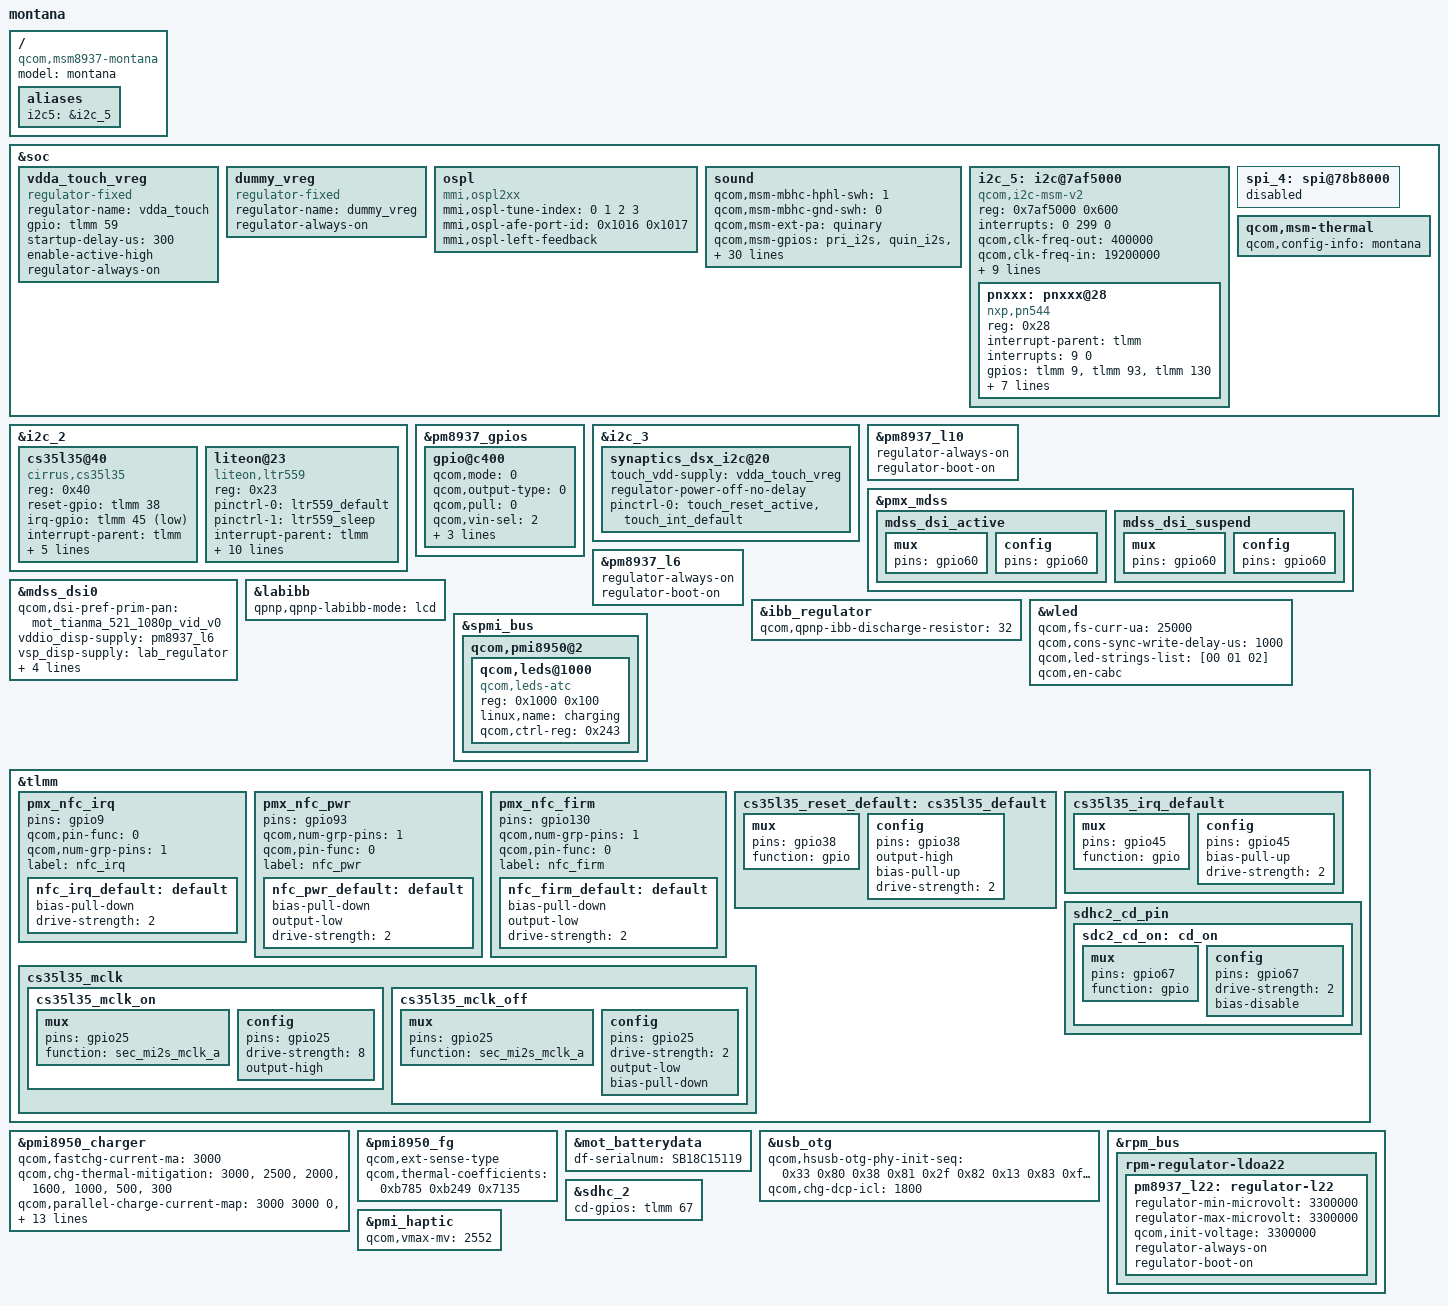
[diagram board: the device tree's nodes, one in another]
/* Copyright (c) 2016, Motorola Mobility Inc. All rights reserved.
 *
 * This program is free software; you can redistribute it and/or modify
 * it under the terms of the GNU General Public License version 2 and
 * only version 2 as published by the Free Software Foundation.
 *
 * This program is distributed in the hope that it will be useful,
 * but WITHOUT ANY WARRANTY; without even the implied warranty of
 * MERCHANTABILITY or FITNESS FOR A PARTICULAR PURPOSE.  See the
 * GNU General Public License for more details.
 */

#include "msm8937-moto-common.dtsi"
#include "dsi-panel-mot-tianma-521-1080p-video.dtsi"
#include "dsi-panel-mot-inx-521-1080p-video.dtsi"
#include "msm8937-camera-sensor-mot-montana.dtsi"
#include "msm8937-montana-fps.dtsi"

 / {
	model = "montana";
	compatible = "qcom,msm8937-montana", "qcom,msm8937-moto",
			"qcom,msm8937";
	aliases {
		i2c5 = &i2c_5;
	};
};

&soc {
	vdda_touch_vreg: vdda_touch_vreg {
		compatible = "regulator-fixed";
		regulator-name = "vdda_touch";
		gpio = <&tlmm 59 0>;
		startup-delay-us = <300>;
		enable-active-high;
		regulator-always-on;
	};

	dummy_vreg: dummy_vreg {
		compatible = "regulator-fixed";
		status = "ok";
		regulator-name = "dummy_vreg";
		regulator-always-on;
	};

	ospl {
		compatible = "mmi,ospl2xx";
		status = "ok";
		mmi,ospl-tune-index = <0 1 2 3>;
		mmi,ospl-afe-port-id = <0x1016 0x1017>;
		mmi,ospl-left-feedback;
	};

	sound {
		qcom,msm-mbhc-hphl-swh = <1>;
		qcom,msm-mbhc-gnd-swh = <0>;
		qcom,msm-ext-pa = "quinary";
		/delete-property/ qcom,cdc-us-euro-gpios;
		/delete-property/ qcom,msm-micbias1-ext-cap;
		/delete-property/ qcom,msm-micbias2-ext-cap;
		qcom,msm-gpios =
			"pri_i2s",
			"quin_i2s",
			"cs35l35_mclk";
		qcom,pinctrl-names =
			"all_off",
			"pri_i2s_act",
			"quin_act",
			"quin_pri_i2s_act",
			"cs35l35_mclk_act",
			"cs35l35_mclk_pri_i2s_act",
			"cs35l35_mclk_quin_act",
			"cs35l35_mclk_quin_pri_i2s_act";
		pinctrl-names =
			"all_off",
			"pri_i2s_act",
			"quin_act",
			"quin_pri_i2s_act",
			"cs35l35_mclk_act",
			"cs35l35_mclk_pri_i2s_act",
			"cs35l35_mclk_quin_act",
			"cs35l35_mclk_quin_pri_i2s_act";
		pinctrl-0 = <&cdc_pdm_lines_sus &cdc_pdm_lines_2_sus
			&pri_tlmm_lines_sus &pri_tlmm_ws_sus &cs35l35_mclk_off>;
		pinctrl-1 = <&cdc_pdm_lines_act &cdc_pdm_lines_2_act
			&pri_tlmm_lines_sus &pri_tlmm_ws_sus &cs35l35_mclk_off>;
		pinctrl-2 = <&cdc_pdm_lines_sus &cdc_pdm_lines_2_sus
			&pri_tlmm_lines_act &pri_tlmm_ws_act &cs35l35_mclk_off>;
		pinctrl-3 = <&cdc_pdm_lines_act &cdc_pdm_lines_2_act
			&pri_tlmm_lines_act &pri_tlmm_ws_act &cs35l35_mclk_off>;
		pinctrl-4 = <&cdc_pdm_lines_sus &cdc_pdm_lines_2_sus
			&pri_tlmm_lines_sus &pri_tlmm_ws_sus &cs35l35_mclk_on>;
		pinctrl-5 = <&cdc_pdm_lines_act &cdc_pdm_lines_2_act
			&pri_tlmm_lines_sus &pri_tlmm_ws_sus &cs35l35_mclk_on>;
		pinctrl-6 = <&cdc_pdm_lines_sus &cdc_pdm_lines_2_sus
			&pri_tlmm_lines_act &pri_tlmm_ws_act &cs35l35_mclk_on>;
		pinctrl-7 = <&cdc_pdm_lines_act &cdc_pdm_lines_2_act
			&pri_tlmm_lines_act &pri_tlmm_ws_act &cs35l35_mclk_on>;
	};

	i2c_5: i2c@7af5000 { /* BLSP2 QUP1 */
		status = "okay";
		compatible = "qcom,i2c-msm-v2";
		#address-cells = <1>;
		#size-cells = <0>;
		reg-names = "qup_phys_addr";
		reg = <0x7af5000 0x600>;
		interrupt-names = "qup_irq";
		interrupts = <0 299 0>;
		qcom,clk-freq-out = <400000>;
		qcom,clk-freq-in  = <19200000>;
		clock-names = "iface_clk", "core_clk";
		clocks = <&clock_gcc clk_gcc_blsp2_ahb_clk>,
			<&clock_gcc clk_gcc_blsp2_qup1_i2c_apps_clk>;

		pinctrl-names = "i2c_active", "i2c_sleep";
		pinctrl-0 = <&i2c_5_active>;
		pinctrl-1 = <&i2c_5_sleep>;
		qcom,noise-rjct-scl = <0>;
		qcom,noise-rjct-sda = <0>;
		qcom,master-id = <84>;
		dmas = <&dma_blsp2 4 64 0x20000020 0x20>,
			<&dma_blsp2 5 32 0x20000020 0x20>;
		dma-names = "tx", "rx";
	};

        spi_4: spi@78b8000 { /* BLSP1 QUP4 */
                status = "disabled";
                /delete-node/ stml0xx@0;
        };

	qcom,msm-thermal {
		qcom,config-info = "montana";
	};
};

&i2c_2 {
	/delete-node/ adv7533@39;
	/delete-node/ pericom-type-c@1d;

	cs35l35@40 {
		compatible = "cirrus,cs35l35";
		reg = <0x40>;
		reset-gpio = <&tlmm 38 0>;
		irq-gpio = <&tlmm 45 1>;
		interrupt-parent = <&tlmm>;
		interrupts = <45 8>;

		VA-supply = <&dummy_vreg>;
		VP-supply = <&dummy_vreg>;
		pinctrl-names = "default";
		pinctrl-0 = <&cs35l35_irq_default &cs35l35_reset_default>;
	};

	liteon@23 {
		compatible = "liteon,ltr559";
		reg = <0x23>;
		pinctrl-names = "default","sleep";
		pinctrl-0 = <&ltr559_default>;
		pinctrl-1 = <&ltr559_sleep>;
		interrupt-parent = <&tlmm>;
		interrupts = <46 0x2>;
		vdd-supply = <&pm8937_l10>;
		vio-supply = <&pm8937_l6>;
		ltr,irq-gpio = <&tlmm 46 0x2>;
		ltr,ps-faroffset = <30>;
		ltr,ps-nearoffset = <40>;
		ltr,ps-threshold = <800>;
		ltr,ps-hysteresis-threshold = <300>;
		ltr,als-polling-time = <200>;
		ltr,prox-sensor-name = "Rear Proximity sensor";
	};
};

&pm8937_gpios {
	gpio@c400 {
		qcom,mode = <0>;
		qcom,output-type = <0>;
		qcom,pull = <0>;
		qcom,vin-sel = <2>;
		qcom,out-strength = <3>;
		qcom,src-sel = <0>;
		qcom,master-en = <1>;
		status = "okay";
	};
};

&i2c_5 { /* BLSP2 QUP1 (NFC) */
	pnxxx: pnxxx@28 {
	    compatible = "nxp,pn544";
	    reg = <0x28>;
	    interrupt-parent = <&tlmm>;
	    interrupts = <9 0>;
	    gpios = <&tlmm 9 0>, /* IRQ */
	    <&tlmm 93 0>, /* VEN */
	    <&tlmm 130 0>; /* Firmware */

	    nxp,pnxxx-discharge-delay = <100>;
	    nxp,pnxxx-ven-inv-polarity = <0>;

	    pinctrl-names = "default";
	    pinctrl-0=<&nfc_irq_default &nfc_pwr_default &nfc_firm_default>;

	    qcom,clk-gpio = <&pm8937_gpios 5 0x00>;
	    qcom,clk-src = "BBCLK2";
	    clocks = <&clock_gcc clk_bb_clk2_pin>;
	    clock-names = "ref_clk";
	};
};

&i2c_3 {
	synaptics_dsx_i2c@20 {
		touch_vdd-supply = <&vdda_touch_vreg>;
		regulator-power-off-no-delay;
		pinctrl-0 = <&touch_reset_active &touch_int_default>;
	};
};

&pm8937_l10 {
	regulator-always-on;
	regulator-boot-on;
};

&pmx_mdss {
	mdss_dsi_active {
		mux {
			pins = "gpio60";
		};

		config {
			pins = "gpio60";
		};
	};

	mdss_dsi_suspend {
		mux {
			pins = "gpio60";
		};

		config {
			pins = "gpio60";
		};
	};
};

&pm8937_l6 {
	regulator-always-on;
	regulator-boot-on;
};

&mdss_dsi0 {
	qcom,dsi-pref-prim-pan = <&mot_tianma_521_1080p_vid_v0>;
	vddio_disp-supply = <&pm8937_l6>;
	vsp_disp-supply = <&lab_regulator>;
	vsn_disp-supply = <&ibb_regulator>;

	pinctrl-names = "mdss_default", "mdss_sleep";
	pinctrl-0 = <&mdss_dsi_active>;
	pinctrl-1 = <&mdss_dsi_suspend>;

	qcom,platform-reset-gpio = <&tlmm 60 0>;
};

/* display boost and inverting boost regulators */
&labibb {
	status = "ok";
	qpnp,qpnp-labibb-mode = "lcd";
};

&ibb_regulator {
	qcom,qpnp-ibb-discharge-resistor = <32>;
};

&wled {
	qcom,fs-curr-ua = <25000>;
	qcom,cons-sync-write-delay-us = <1000>;
	qcom,led-strings-list = [00 01 02];
	qcom,en-cabc;
};

&spmi_bus {
	qcom,pmi8950@2 {
		/delete-node/ qcom,leds@a100;

		qcom,leds@1000 {
			status = "ok";
			reg = <0x1000 0x100>;
			compatible = "qcom,leds-atc";
			linux,name = "charging";
			qcom,ctrl-reg = <0x243>;
		};
	};
};

&tlmm{
	pmx_nfc_irq {
		pins = "gpio9";
		qcom,pin-func = <0>;
		qcom,num-grp-pins = <1>;
		label = "nfc_irq";

		nfc_irq_default: default {
			bias-pull-down;
			drive-strength = <2>;
		};
	};

	pmx_nfc_pwr {
		pins = "gpio93";
		qcom,num-grp-pins = <1>;
		qcom,pin-func = <0>;
		label = "nfc_pwr";

		nfc_pwr_default: default {
			bias-pull-down;
			output-low;
			drive-strength = <2>;
		};
	};

	pmx_nfc_firm {
		pins = "gpio130";
		qcom,num-grp-pins = <1>;
		qcom,pin-func = <0>;
		label = "nfc_firm";

		nfc_firm_default: default {
			bias-pull-down;
			output-low;
			drive-strength = <2>;
		};
	};

	cs35l35_reset_default: cs35l35_default{
		mux {
			pins = "gpio38";
			function = "gpio";
		};

		config {
			pins = "gpio38";
			output-high;
			bias-pull-up;
			drive-strength = <2>;
		};
	};

	cs35l35_irq_default: cs35l35_irq_default {
		mux {
			pins = "gpio45";
			function = "gpio";
		};

		config {
			pins = "gpio45";
			bias-pull-up;
			drive-strength = <2>;
		};
	};

	cs35l35_mclk {
		cs35l35_mclk_on: cs35l35_mclk_on {
			mux {
				pins = "gpio25";
				function = "sec_mi2s_mclk_a";
			};

			config {
				pins = "gpio25";
				drive-strength = <8>;
				output-high;
			};
		};

		cs35l35_mclk_off: cs35l35_mclk_off {
			mux {
				pins = "gpio25";
				function = "sec_mi2s_mclk_a";
			};

			config {
				pins = "gpio25";
				drive-strength = <2>;
				output-low;
				bias-pull-down;
			};
		};
	};

	sdhc2_cd_pin {
                sdc2_cd_on: cd_on {
				mux {
                                        pins = "gpio67";
                                        function = "gpio";
                                };

                                config {
                                        pins = "gpio67";
                                        drive-strength = <2>;
                        		/delete-property/ bias-pull-up;
                        		bias-disable;
                                };
                };
        };
};

&pmi8950_charger {
	qcom,fastchg-current-ma = <3000>;
	qcom,chg-thermal-mitigation = <3000>, <2500>, <2000>, <1600>,
		<1000>, <500>, <300>;
	/delete-property/ qcom,dc-thermal-mitigation;
	qcom,parallel-charge-current-map = <3000 3000 0>,
					   <2500 2500 0>,
					   <2000 2000 0>,
					   <1600 1600 0>,
					   <1000 1000 0>,
					   <500 500 0>,
					   <400 400 0>;
	qcom,stepchg-voltage-mv = <4200>;
	qcom,stepchg-current-ma = <2000>;
	qcom,stepchg-taper-ma = <1800>;
	qcom,stepchg-iterm-ma = <125>;
	qcom,temp-warm-current-ma = <1500>;
	qcom,temp-cool-current-ma = <600>;
	qcom,temp-slightly-cool-current-ma = <600>;
	qcom,slightly-cool-temp-c = <15>;
	qcom,enable-charging-limit;
	qcom,upper-limit-capacity = <80>;
	qcom,lower-limit-capacity = <60>;
};

&pmi8950_fg {
	qcom,ext-sense-type; /* External Sense Resistor */
	qcom,thermal-coefficients =  /bits/ 16 <0xb785 0xb249 0x7135>;
};

&mot_batterydata {
	df-serialnum = "SB18C15119";
	#include "batterydata-hg30-atl.dtsi"
	#include "batterydata-hg30-swd.dtsi"
};

&usb_otg {
	qcom,hsusb-otg-phy-init-seq =
		<0x33 0x80 0x38 0x81 0x2f 0x82 0x13 0x83 0xffffffff>;
	qcom,chg-dcp-icl = <1800>;
};

&rpm_bus {
	rpm-regulator-ldoa22 {
		status = "okay";
		pm8937_l22: regulator-l22 {
			regulator-min-microvolt = <3300000>;
			regulator-max-microvolt = <3300000>;
			qcom,init-voltage = <3300000>;
			regulator-always-on;
			regulator-boot-on;
			status = "okay";
		};
	};
};

&sdhc_2 {
	cd-gpios = <&tlmm 67 0x0>;
};

&pmi_haptic {
	qcom,vmax-mv = <2552>;
};

